AUTOSAR XML (schema 4-2-2)
package /AUTOSAR_NvM/PortInterfaces
  6 x client server interface, all with is-service=true:
    NvMAdmin
      operation SetBlockProtection: possible-error=NvMAdmin/E_NOT_OK
        arg ProtectionEnabled: type=boolean, direction=IN
      error E_NOT_OK: error-code=1
    NvMMirror
      operation ReadRamBlockFromNvM: possible-error=NvMMirror/E_NOT_OK
        arg SrcPtr: type=NvM_Rb_VoidPtr, direction=IN
      operation WriteRamBlockToNvM: possible-error=NvMMirror/E_NOT_OK
        arg DstPtr: type=NvM_Rb_VoidPtr, direction=IN
      error E_NOT_OK: error-code=1
    NvMNotifyInitBlock
      operation InitBlock: possible-error=NvMNotifyInitBlock/E_NOT_OK
      error E_NOT_OK: error-code=1
    NvMNotifyJobFinished
      operation JobFinished: possible-error=NvMNotifyJobFinished/E_NOT_OK
        arg ServiceId: type=uint8, direction=IN
        arg JobResult: type=NvM_RequestResultType, direction=IN
      error E_NOT_OK: error-code=1
    NvMRbNotifyJobStarted
      operation JobStarted
        arg ServiceId: type=uint8, direction=IN
    NvMService
      12 x operation, all with possible-error=NvMService/E_NOT_OK:
        EraseBlock
        GetDataIndex
          arg DataIndexPtr: type=uint8, direction=OUT
        GetErrorStatus
          arg RequestResultPtr: type=NvM_RequestResultType, direction=OUT
        InvalidateNvBlock
        ReadBlock
          arg DstPtr: type=NvM_Rb_VoidPtr, direction=IN
        ReadPRAMBlock
        RestoreBlockDefaults
          arg DstPtr: type=NvM_Rb_VoidPtr, direction=IN
        RestorePRAMBlockDefaults
        SetDataIndex
          arg DataIndex: type=uint8, direction=IN
        SetRamBlockStatus
          arg BlockChanged: type=boolean, direction=IN
        WriteBlock
          arg SrcPtr: type=NvM_Rb_ConstVoidPtr, direction=IN
        WritePRAMBlock
      error E_NOT_OK: error-code=1
package /AUTOSAR_NvM/SwcImplementations
  swc implementation NvM: programming-language=C, swc-bsw-mapping=NvM, vendor-id=6, behavior=NVRAMManager
    code-descriptors:
      code CodeDescriptor: artifact-descriptors=autosar-engineering-object={short-label=ArEngObj, category=SWSRC}
package /AUTOSAR_NvM/SwComponentTypes
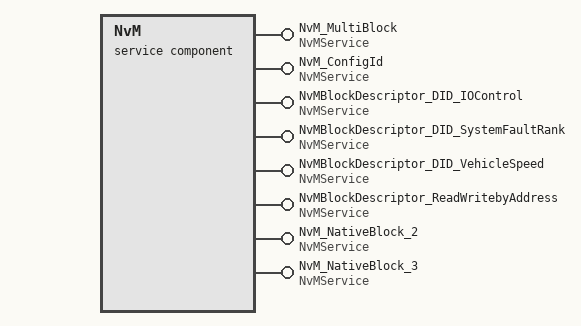
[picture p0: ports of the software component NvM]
  service sw component type NvM
    8 x provide port, all with provided-interface=NvMService:
      NvM_MultiBlock
        provided-com-specs:
          operation=EraseBlock, queue-length=1
          operation=GetDataIndex, queue-length=1
          operation=GetErrorStatus, queue-length=1
          operation=InvalidateNvBlock, queue-length=1
          operation=ReadBlock, queue-length=1
          operation=ReadPRAMBlock, queue-length=1
          operation=RestoreBlockDefaults, queue-length=1
          operation=RestorePRAMBlockDefaults, queue-length=1
          operation=SetDataIndex, queue-length=1
          operation=SetRamBlockStatus, queue-length=1
          operation=WriteBlock, queue-length=1
          operation=WritePRAMBlock, queue-length=1
      NvM_ConfigId
        provided-com-specs:
          operation=EraseBlock, queue-length=1
          operation=GetDataIndex, queue-length=1
          operation=GetErrorStatus, queue-length=1
          operation=InvalidateNvBlock, queue-length=1
          operation=ReadBlock, queue-length=1
          operation=ReadPRAMBlock, queue-length=1
          operation=RestoreBlockDefaults, queue-length=1
          operation=RestorePRAMBlockDefaults, queue-length=1
          operation=SetDataIndex, queue-length=1
          operation=SetRamBlockStatus, queue-length=1
          operation=WriteBlock, queue-length=1
          operation=WritePRAMBlock, queue-length=1
      NvMBlockDescriptor_DID_IOControl
        provided-com-specs:
          operation=EraseBlock, queue-length=1
          operation=GetDataIndex, queue-length=1
          operation=GetErrorStatus, queue-length=1
          operation=InvalidateNvBlock, queue-length=1
          operation=ReadBlock, queue-length=1
          operation=ReadPRAMBlock, queue-length=1
          operation=RestoreBlockDefaults, queue-length=1
          operation=RestorePRAMBlockDefaults, queue-length=1
          operation=SetDataIndex, queue-length=1
          operation=SetRamBlockStatus, queue-length=1
          operation=WriteBlock, queue-length=1
          operation=WritePRAMBlock, queue-length=1
      NvMBlockDescriptor_DID_SystemFaultRank
        provided-com-specs:
          operation=EraseBlock, queue-length=1
          operation=GetDataIndex, queue-length=1
          operation=GetErrorStatus, queue-length=1
          operation=InvalidateNvBlock, queue-length=1
          operation=ReadBlock, queue-length=1
          operation=ReadPRAMBlock, queue-length=1
          operation=RestoreBlockDefaults, queue-length=1
          operation=RestorePRAMBlockDefaults, queue-length=1
          operation=SetDataIndex, queue-length=1
          operation=SetRamBlockStatus, queue-length=1
          operation=WriteBlock, queue-length=1
          operation=WritePRAMBlock, queue-length=1
      NvMBlockDescriptor_DID_VehicleSpeed
        provided-com-specs:
          operation=EraseBlock, queue-length=1
          operation=GetDataIndex, queue-length=1
          operation=GetErrorStatus, queue-length=1
          operation=InvalidateNvBlock, queue-length=1
          operation=ReadBlock, queue-length=1
          operation=ReadPRAMBlock, queue-length=1
          operation=RestoreBlockDefaults, queue-length=1
          operation=RestorePRAMBlockDefaults, queue-length=1
          operation=SetDataIndex, queue-length=1
          operation=SetRamBlockStatus, queue-length=1
          operation=WriteBlock, queue-length=1
          operation=WritePRAMBlock, queue-length=1
      NvMBlockDescriptor_ReadWritebyAddress
        provided-com-specs:
          operation=EraseBlock, queue-length=1
          operation=GetDataIndex, queue-length=1
          operation=GetErrorStatus, queue-length=1
          operation=InvalidateNvBlock, queue-length=1
          operation=ReadBlock, queue-length=1
          operation=ReadPRAMBlock, queue-length=1
          operation=RestoreBlockDefaults, queue-length=1
          operation=RestorePRAMBlockDefaults, queue-length=1
          operation=SetDataIndex, queue-length=1
          operation=SetRamBlockStatus, queue-length=1
          operation=WriteBlock, queue-length=1
          operation=WritePRAMBlock, queue-length=1
      NvM_NativeBlock_2
        provided-com-specs:
          operation=EraseBlock, queue-length=1
          operation=GetDataIndex, queue-length=1
          operation=GetErrorStatus, queue-length=1
          operation=InvalidateNvBlock, queue-length=1
          operation=ReadBlock, queue-length=1
          operation=ReadPRAMBlock, queue-length=1
          operation=RestoreBlockDefaults, queue-length=1
          operation=RestorePRAMBlockDefaults, queue-length=1
          operation=SetDataIndex, queue-length=1
          operation=SetRamBlockStatus, queue-length=1
          operation=WriteBlock, queue-length=1
          operation=WritePRAMBlock, queue-length=1
      NvM_NativeBlock_3
        provided-com-specs:
          operation=EraseBlock, queue-length=1
          operation=GetDataIndex, queue-length=1
          operation=GetErrorStatus, queue-length=1
          operation=InvalidateNvBlock, queue-length=1
          operation=ReadBlock, queue-length=1
          operation=ReadPRAMBlock, queue-length=1
          operation=RestoreBlockDefaults, queue-length=1
          operation=RestorePRAMBlockDefaults, queue-length=1
          operation=SetDataIndex, queue-length=1
          operation=SetRamBlockStatus, queue-length=1
          operation=WriteBlock, queue-length=1
          operation=WritePRAMBlock, queue-length=1
    behavior NVRAMManager
      96 x operation invoked event:
        EENB_NvM_MultiBlock: start-on-event=EraseNvBlock, operation=NvM_MultiBlock.EraseBlock
        EGDI_NvM_MultiBlock: start-on-event=GetDataIndex, operation=NvM_MultiBlock.GetDataIndex
        EGES_NvM_MultiBlock: start-on-event=GetErrorStatus, operation=NvM_MultiBlock.GetErrorStatus
        EINB_NvM_MultiBlock: start-on-event=InvalidateNvBlock, operation=NvM_MultiBlock.InvalidateNvBlock
        ERBL_NvM_MultiBlock: start-on-event=ReadBlock, operation=NvM_MultiBlock.ReadBlock
        ERPBL_NvM_MultiBlock: start-on-event=ReadPRAMBlock, operation=NvM_MultiBlock.ReadPRAMBlock
        ERBD_NvM_MultiBlock: start-on-event=RestoreBlockDefaults, operation=NvM_MultiBlock.RestoreBlockDefaults
        ERPBD_NvM_MultiBlock: start-on-event=RestorePRAMBlockDefaults, operation=NvM_MultiBlock.RestorePRAMBlockDefaults
        ESDI_NvM_MultiBlock: start-on-event=SetDataIndex, operation=NvM_MultiBlock.SetDataIndex
        ESRS_NvM_MultiBlock: start-on-event=SetRamBlockStatus, operation=NvM_MultiBlock.SetRamBlockStatus
        EWBL_NvM_MultiBlock: start-on-event=WriteBlock, operation=NvM_MultiBlock.WriteBlock
        EWPBL_NvM_MultiBlock: start-on-event=WritePRAMBlock, operation=NvM_MultiBlock.WritePRAMBlock
        EENB_NvM_ConfigId: start-on-event=EraseNvBlock, operation=NvM_ConfigId.EraseBlock
        EGDI_NvM_ConfigId: start-on-event=GetDataIndex, operation=NvM_ConfigId.GetDataIndex
        EGES_NvM_ConfigId: start-on-event=GetErrorStatus, operation=NvM_ConfigId.GetErrorStatus
        EINB_NvM_ConfigId: start-on-event=InvalidateNvBlock, operation=NvM_ConfigId.InvalidateNvBlock
        ERBL_NvM_ConfigId: start-on-event=ReadBlock, operation=NvM_ConfigId.ReadBlock
        ERPBL_NvM_ConfigId: start-on-event=ReadPRAMBlock, operation=NvM_ConfigId.ReadPRAMBlock
        ERBD_NvM_ConfigId: start-on-event=RestoreBlockDefaults, operation=NvM_ConfigId.RestoreBlockDefaults
        ERPBD_NvM_ConfigId: start-on-event=RestorePRAMBlockDefaults, operation=NvM_ConfigId.RestorePRAMBlockDefaults
        ESDI_NvM_ConfigId: start-on-event=SetDataIndex, operation=NvM_ConfigId.SetDataIndex
        ESRS_NvM_ConfigId: start-on-event=SetRamBlockStatus, operation=NvM_ConfigId.SetRamBlockStatus
        EWBL_NvM_ConfigId: start-on-event=WriteBlock, operation=NvM_ConfigId.WriteBlock
        EWPBL_NvM_ConfigId: start-on-event=WritePRAMBlock, operation=NvM_ConfigId.WritePRAMBlock
        EENB_NvMBlockDescriptor_DID_IOControl: start-on-event=EraseNvBlock, operation=NvMBlockDescriptor_DID_IOControl.EraseBlock
        EGDI_NvMBlockDescriptor_DID_IOControl: start-on-event=GetDataIndex, operation=NvMBlockDescriptor_DID_IOControl.GetDataIndex
        EGES_NvMBlockDescriptor_DID_IOControl: start-on-event=GetErrorStatus, operation=NvMBlockDescriptor_DID_IOControl.GetErrorStatus
        EINB_NvMBlockDescriptor_DID_IOControl: start-on-event=InvalidateNvBlock, operation=NvMBlockDescriptor_DID_IOControl.InvalidateNvBlock
        ERBL_NvMBlockDescriptor_DID_IOControl: start-on-event=ReadBlock, operation=NvMBlockDescriptor_DID_IOControl.ReadBlock
        ERPBL_NvMBlockDescriptor_DID_IOControl: start-on-event=ReadPRAMBlock, operation=NvMBlockDescriptor_DID_IOControl.ReadPRAMBlock
        ERBD_NvMBlockDescriptor_DID_IOControl: start-on-event=RestoreBlockDefaults, operation=NvMBlockDescriptor_DID_IOControl.RestoreBlockDefaults
        ERPBD_NvMBlockDescriptor_DID_IOControl: start-on-event=RestorePRAMBlockDefaults, operation=NvMBlockDescriptor_DID_IOControl.RestorePRAMBlockDefaults
        ESDI_NvMBlockDescriptor_DID_IOControl: start-on-event=SetDataIndex, operation=NvMBlockDescriptor_DID_IOControl.SetDataIndex
        ESRS_NvMBlockDescriptor_DID_IOControl: start-on-event=SetRamBlockStatus, operation=NvMBlockDescriptor_DID_IOControl.SetRamBlockStatus
        EWBL_NvMBlockDescriptor_DID_IOControl: start-on-event=WriteBlock, operation=NvMBlockDescriptor_DID_IOControl.WriteBlock
        EWPBL_NvMBlockDescriptor_DID_IOControl: start-on-event=WritePRAMBlock, operation=NvMBlockDescriptor_DID_IOControl.WritePRAMBlock
        EENB_NvMBlockDescriptor_DID_SystemFaultRank: start-on-event=EraseNvBlock, operation=NvMBlockDescriptor_DID_SystemFaultRank.EraseBlock
        EGDI_NvMBlockDescriptor_DID_SystemFaultRank: start-on-event=GetDataIndex, operation=NvMBlockDescriptor_DID_SystemFaultRank.GetDataIndex
        EGES_NvMBlockDescriptor_DID_SystemFaultRank: start-on-event=GetErrorStatus, operation=NvMBlockDescriptor_DID_SystemFaultRank.GetErrorStatus
        EINB_NvMBlockDescriptor_DID_SystemFaultRank: start-on-event=InvalidateNvBlock, operation=NvMBlockDescriptor_DID_SystemFaultRank.InvalidateNvBlock
        ERBL_NvMBlockDescriptor_DID_SystemFaultRank: start-on-event=ReadBlock, operation=NvMBlockDescriptor_DID_SystemFaultRank.ReadBlock
        ERPBL_NvMBlockDescriptor_DID_SystemFaultRank: start-on-event=ReadPRAMBlock, operation=NvMBlockDescriptor_DID_SystemFaultRank.ReadPRAMBlock
        ERBD_NvMBlockDescriptor_DID_SystemFaultRank: start-on-event=RestoreBlockDefaults, operation=NvMBlockDescriptor_DID_SystemFaultRank.RestoreBlockDefaults
        ERPBD_NvMBlockDescriptor_DID_SystemFaultRank: start-on-event=RestorePRAMBlockDefaults, operation=NvMBlockDescriptor_DID_SystemFaultRank.RestorePRAMBlockDefaults
        ESDI_NvMBlockDescriptor_DID_SystemFaultRank: start-on-event=SetDataIndex, operation=NvMBlockDescriptor_DID_SystemFaultRank.SetDataIndex
        ESRS_NvMBlockDescriptor_DID_SystemFaultRank: start-on-event=SetRamBlockStatus, operation=NvMBlockDescriptor_DID_SystemFaultRank.SetRamBlockStatus
        EWBL_NvMBlockDescriptor_DID_SystemFaultRank: start-on-event=WriteBlock, operation=NvMBlockDescriptor_DID_SystemFaultRank.WriteBlock
        EWPBL_NvMBlockDescriptor_DID_SystemFaultRank: start-on-event=WritePRAMBlock, operation=NvMBlockDescriptor_DID_SystemFaultRank.WritePRAMBlock
        EENB_NvMBlockDescriptor_DID_VehicleSpeed: start-on-event=EraseNvBlock, operation=NvMBlockDescriptor_DID_VehicleSpeed.EraseBlock
        EGDI_NvMBlockDescriptor_DID_VehicleSpeed: start-on-event=GetDataIndex, operation=NvMBlockDescriptor_DID_VehicleSpeed.GetDataIndex
        EGES_NvMBlockDescriptor_DID_VehicleSpeed: start-on-event=GetErrorStatus, operation=NvMBlockDescriptor_DID_VehicleSpeed.GetErrorStatus
        EINB_NvMBlockDescriptor_DID_VehicleSpeed: start-on-event=InvalidateNvBlock, operation=NvMBlockDescriptor_DID_VehicleSpeed.InvalidateNvBlock
        ERBL_NvMBlockDescriptor_DID_VehicleSpeed: start-on-event=ReadBlock, operation=NvMBlockDescriptor_DID_VehicleSpeed.ReadBlock
        ERPBL_NvMBlockDescriptor_DID_VehicleSpeed: start-on-event=ReadPRAMBlock, operation=NvMBlockDescriptor_DID_VehicleSpeed.ReadPRAMBlock
        ERBD_NvMBlockDescriptor_DID_VehicleSpeed: start-on-event=RestoreBlockDefaults, operation=NvMBlockDescriptor_DID_VehicleSpeed.RestoreBlockDefaults
        ERPBD_NvMBlockDescriptor_DID_VehicleSpeed: start-on-event=RestorePRAMBlockDefaults, operation=NvMBlockDescriptor_DID_VehicleSpeed.RestorePRAMBlockDefaults
        ESDI_NvMBlockDescriptor_DID_VehicleSpeed: start-on-event=SetDataIndex, operation=NvMBlockDescriptor_DID_VehicleSpeed.SetDataIndex
        ESRS_NvMBlockDescriptor_DID_VehicleSpeed: start-on-event=SetRamBlockStatus, operation=NvMBlockDescriptor_DID_VehicleSpeed.SetRamBlockStatus
        EWBL_NvMBlockDescriptor_DID_VehicleSpeed: start-on-event=WriteBlock, operation=NvMBlockDescriptor_DID_VehicleSpeed.WriteBlock
        EWPBL_NvMBlockDescriptor_DID_VehicleSpeed: start-on-event=WritePRAMBlock, operation=NvMBlockDescriptor_DID_VehicleSpeed.WritePRAMBlock
        EENB_NvMBlockDescriptor_ReadWritebyAddress: start-on-event=EraseNvBlock, operation=NvMBlockDescriptor_ReadWritebyAddress.EraseBlock
        EGDI_NvMBlockDescriptor_ReadWritebyAddress: start-on-event=GetDataIndex, operation=NvMBlockDescriptor_ReadWritebyAddress.GetDataIndex
        EGES_NvMBlockDescriptor_ReadWritebyAddress: start-on-event=GetErrorStatus, operation=NvMBlockDescriptor_ReadWritebyAddress.GetErrorStatus
        EINB_NvMBlockDescriptor_ReadWritebyAddress: start-on-event=InvalidateNvBlock, operation=NvMBlockDescriptor_ReadWritebyAddress.InvalidateNvBlock
        ERBL_NvMBlockDescriptor_ReadWritebyAddress: start-on-event=ReadBlock, operation=NvMBlockDescriptor_ReadWritebyAddress.ReadBlock
        ERPBL_NvMBlockDescriptor_ReadWritebyAddress: start-on-event=ReadPRAMBlock, operation=NvMBlockDescriptor_ReadWritebyAddress.ReadPRAMBlock
        ERBD_NvMBlockDescriptor_ReadWritebyAddress: start-on-event=RestoreBlockDefaults, operation=NvMBlockDescriptor_ReadWritebyAddress.RestoreBlockDefaults
        ERPBD_NvMBlockDescriptor_ReadWritebyAddress: start-on-event=RestorePRAMBlockDefaults, operation=NvMBlockDescriptor_ReadWritebyAddress.RestorePRAMBlockDefaults
        ESDI_NvMBlockDescriptor_ReadWritebyAddress: start-on-event=SetDataIndex, operation=NvMBlockDescriptor_ReadWritebyAddress.SetDataIndex
        ESRS_NvMBlockDescriptor_ReadWritebyAddress: start-on-event=SetRamBlockStatus, operation=NvMBlockDescriptor_ReadWritebyAddress.SetRamBlockStatus
        EWBL_NvMBlockDescriptor_ReadWritebyAddress: start-on-event=WriteBlock, operation=NvMBlockDescriptor_ReadWritebyAddress.WriteBlock
        EWPBL_NvMBlockDescriptor_ReadWritebyAddress: start-on-event=WritePRAMBlock, operation=NvMBlockDescriptor_ReadWritebyAddress.WritePRAMBlock
        EENB_NvM_NativeBlock_2: start-on-event=EraseNvBlock, operation=NvM_NativeBlock_2.EraseBlock
        EGDI_NvM_NativeBlock_2: start-on-event=GetDataIndex, operation=NvM_NativeBlock_2.GetDataIndex
        EGES_NvM_NativeBlock_2: start-on-event=GetErrorStatus, operation=NvM_NativeBlock_2.GetErrorStatus
        EINB_NvM_NativeBlock_2: start-on-event=InvalidateNvBlock, operation=NvM_NativeBlock_2.InvalidateNvBlock
        ERBL_NvM_NativeBlock_2: start-on-event=ReadBlock, operation=NvM_NativeBlock_2.ReadBlock
        ERPBL_NvM_NativeBlock_2: start-on-event=ReadPRAMBlock, operation=NvM_NativeBlock_2.ReadPRAMBlock
        ERBD_NvM_NativeBlock_2: start-on-event=RestoreBlockDefaults, operation=NvM_NativeBlock_2.RestoreBlockDefaults
        ERPBD_NvM_NativeBlock_2: start-on-event=RestorePRAMBlockDefaults, operation=NvM_NativeBlock_2.RestorePRAMBlockDefaults
        ESDI_NvM_NativeBlock_2: start-on-event=SetDataIndex, operation=NvM_NativeBlock_2.SetDataIndex
        ESRS_NvM_NativeBlock_2: start-on-event=SetRamBlockStatus, operation=NvM_NativeBlock_2.SetRamBlockStatus
        EWBL_NvM_NativeBlock_2: start-on-event=WriteBlock, operation=NvM_NativeBlock_2.WriteBlock
        EWPBL_NvM_NativeBlock_2: start-on-event=WritePRAMBlock, operation=NvM_NativeBlock_2.WritePRAMBlock
        EENB_NvM_NativeBlock_3: start-on-event=EraseNvBlock, operation=NvM_NativeBlock_3.EraseBlock
        EGDI_NvM_NativeBlock_3: start-on-event=GetDataIndex, operation=NvM_NativeBlock_3.GetDataIndex
        EGES_NvM_NativeBlock_3: start-on-event=GetErrorStatus, operation=NvM_NativeBlock_3.GetErrorStatus
        EINB_NvM_NativeBlock_3: start-on-event=InvalidateNvBlock, operation=NvM_NativeBlock_3.InvalidateNvBlock
        ERBL_NvM_NativeBlock_3: start-on-event=ReadBlock, operation=NvM_NativeBlock_3.ReadBlock
        ERPBL_NvM_NativeBlock_3: start-on-event=ReadPRAMBlock, operation=NvM_NativeBlock_3.ReadPRAMBlock
        ERBD_NvM_NativeBlock_3: start-on-event=RestoreBlockDefaults, operation=NvM_NativeBlock_3.RestoreBlockDefaults
        ERPBD_NvM_NativeBlock_3: start-on-event=RestorePRAMBlockDefaults, operation=NvM_NativeBlock_3.RestorePRAMBlockDefaults
        ESDI_NvM_NativeBlock_3: start-on-event=SetDataIndex, operation=NvM_NativeBlock_3.SetDataIndex
        ESRS_NvM_NativeBlock_3: start-on-event=SetRamBlockStatus, operation=NvM_NativeBlock_3.SetRamBlockStatus
        EWBL_NvM_NativeBlock_3: start-on-event=WriteBlock, operation=NvM_NativeBlock_3.WriteBlock
        EWPBL_NvM_NativeBlock_3: start-on-event=WritePRAMBlock, operation=NvM_NativeBlock_3.WritePRAMBlock
      port-api-options:
        {enable-take-address=false, indirect-api=false, port-defined-argument-value{value=0, value-type=NvM_BlockIdType}, port=NvM_MultiBlock}
        {enable-take-address=false, indirect-api=false, port-defined-argument-value{value=1, value-type=NvM_BlockIdType}, port=NvM_ConfigId}
        {enable-take-address=false, indirect-api=false, port-defined-argument-value{value=24, value-type=NvM_BlockIdType}, port=NvMBlockDescriptor_DID_IOControl}
        {enable-take-address=false, indirect-api=false, port-defined-argument-value{value=25, value-type=NvM_BlockIdType}, port=NvMBlockDescriptor_DID_SystemFaultRank}
        {enable-take-address=false, indirect-api=false, port-defined-argument-value{value=26, value-type=NvM_BlockIdType}, port=NvMBlockDescriptor_DID_VehicleSpeed}
        {enable-take-address=false, indirect-api=false, port-defined-argument-value{value=27, value-type=NvM_BlockIdType}, port=NvMBlockDescriptor_ReadWritebyAddress}
        {enable-take-address=false, indirect-api=false, port-defined-argument-value{value=28, value-type=NvM_BlockIdType}, port=NvM_NativeBlock_2}
        {enable-take-address=false, indirect-api=false, port-defined-argument-value{value=29, value-type=NvM_BlockIdType}, port=NvM_NativeBlock_3}
      14 x runnable:
        EraseNvBlock: runnable-entity-argument=symbol=BlockId, can-be-invoked-concurrently=true, symbol=NvM_EraseNvBlock
        GetDataIndex: arguments=[symbol=BlockId, symbol=DataIndexPtr], can-be-invoked-concurrently=true, symbol=NvM_GetDataIndex
        GetErrorStatus: arguments=[symbol=BlockId, symbol=RequestResultPtr], can-be-invoked-concurrently=true, symbol=NvM_GetErrorStatus
        InvalidateNvBlock: runnable-entity-argument=symbol=BlockId, can-be-invoked-concurrently=true, symbol=NvM_InvalidateNvBlock
        ReadBlock: arguments=[symbol=BlockId, symbol=NvM_DstPtr], can-be-invoked-concurrently=true, symbol=NvM_ReadBlock
        ReadPRAMBlock: runnable-entity-argument=symbol=BlockId, can-be-invoked-concurrently=true, symbol=NvM_ReadPRAMBlock
        RestoreBlockDefaults: arguments=[symbol=BlockId, symbol=NvM_DstPtr], can-be-invoked-concurrently=true, symbol=NvM_RestoreBlockDefaults
        RestorePRAMBlockDefaults: runnable-entity-argument=symbol=BlockId, can-be-invoked-concurrently=true, symbol=NvM_RestorePRAMBlockDefaults
        SetBlockProtection: arguments=[symbol=BlockId, symbol=ProtectionEnabled], can-be-invoked-concurrently=true, symbol=NvM_SetBlockProtection
        SetDataIndex: arguments=[symbol=BlockId, symbol=DataIndex], can-be-invoked-concurrently=true, symbol=NvM_SetDataIndex
        SetRamBlockStatus: arguments=[symbol=BlockId, symbol=BlockChanged], can-be-invoked-concurrently=true, symbol=NvM_SetRamBlockStatus
        WriteBlock: arguments=[symbol=BlockId, symbol=NvM_SrcPtr], can-be-invoked-concurrently=true, symbol=NvM_WriteBlock
        WritePRAMBlock: runnable-entity-argument=symbol=BlockId, can-be-invoked-concurrently=true, symbol=NvM_WritePRAMBlock
        MainFunction: symbol=NvM_MainFunction
